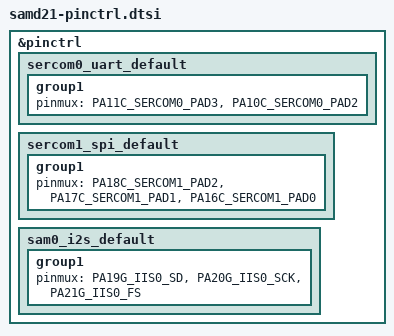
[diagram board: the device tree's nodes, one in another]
/*
 * Copyright (c) 2022, Gerson Fernando Budke <nandojve@gmail.com>
 * SPDX-License-Identifier: Apache-2.0
 */

#include <dt-bindings/pinctrl/samd21-da1gXabcd-pinctrl.h>

&pinctrl {

	sercom0_uart_default: sercom0_uart_default {
		group1 {
			pinmux = <PA11C_SERCOM0_PAD3>,
				 <PA10C_SERCOM0_PAD2>;
		};
	};

	sercom1_spi_default: sercom1_spi_default {
		group1 {
			pinmux = <PA18C_SERCOM1_PAD2>,
				 <PA17C_SERCOM1_PAD1>,
				 <PA16C_SERCOM1_PAD0>;
		};
	};

	sam0_i2s_default: sam0_i2s_default {
		group1 {
			pinmux = <PA19G_IIS0_SD>,
					<PA20G_IIS0_SCK>,
					<PA21G_IIS0_FS>;
		};
	};
};
